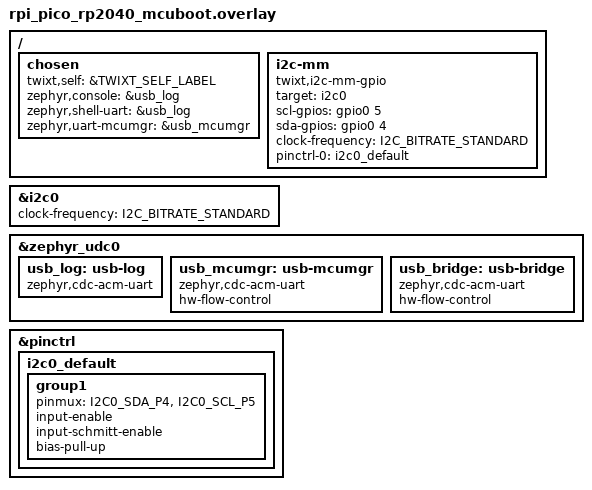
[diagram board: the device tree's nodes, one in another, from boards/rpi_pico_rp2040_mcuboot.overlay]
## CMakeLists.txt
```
# Copyright (c) 2026 Christoph Jans <jans.christoph@gmail.com>
# SPDX-License-Identifier: Apache-2.0

cmake_minimum_required(VERSION 3.20.0)

if(SYSBUILD_CACHE)
  foreach(var MCU ROUTE VERSION)
    file(STRINGS ${SYSBUILD_CACHE} sysbuild_var REGEX "^${var}:")
    if(sysbuild_var)
      string(REGEX REPLACE "^${var}:[A-Z]*=" "" sysbuild_var "${sysbuild_var}")
      set(${var} ${sysbuild_var} CACHE STRING "" FORCE)
    endif()
  endforeach()
endif()
set(MCU pico CACHE STRING "MCU to build: pico, the gateway, or nrf, the one updated")
list(APPEND DTS_EXTRA_CPPFLAGS -DTWIXT_SELF_LABEL=mcu_${MCU})

# ROUTE=service: the twixt MCUmgr service, with twixt,smp-gateway-serial on pico. ROUTE=ble: as
# service, with nrf as the gateway, a twixt,smp-gateway-bt per MCU.
set(ROUTE service CACHE STRING "How SMP gets to the MCUs: service or ble")
if(ROUTE STREQUAL "ble")
  list(APPEND EXTRA_DTC_OVERLAY_FILE ${CMAKE_CURRENT_SOURCE_DIR}/routes/ble_${MCU}.overlay)
  list(APPEND EXTRA_CONF_FILE ${CMAKE_CURRENT_SOURCE_DIR}/routes/ble_${MCU}.conf)
elseif(MCU STREQUAL "pico")
  list(APPEND EXTRA_DTC_OVERLAY_FILE ${CMAKE_CURRENT_SOURCE_DIR}/routes/service_pico.overlay)
endif()

# VERSION: the two builds of nrf that the test updates between
if(VERSION)
  list(APPEND EXTRA_CONF_FILE ${CMAKE_CURRENT_SOURCE_DIR}/routes/version_${VERSION}.conf)
endif()

find_package(Zephyr REQUIRED HINTS $ENV{ZEPHYR_BASE})
project(twixt_smp_update)

target_sources(app PRIVATE src/main.c)
target_sources_ifdef(CONFIG_USB_DEVICE_STACK_NEXT app PRIVATE src/usb.c)
```

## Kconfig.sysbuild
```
# Copyright (c) 2026 Christoph Jans <jans.christoph@gmail.com>
# SPDX-License-Identifier: Apache-2.0

source "share/sysbuild/Kconfig"

config NET_CORE_IMAGE_HCI_IPC
	bool "HCI IPC image on the nRF5340's network core, for ROUTE=ble"
```

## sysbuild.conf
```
# Copyright (c) 2026 Christoph Jans <jans.christoph@gmail.com>
# SPDX-License-Identifier: Apache-2.0

SB_CONFIG_BOOTLOADER_MCUBOOT=y
```

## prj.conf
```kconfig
# Copyright (c) 2026 Christoph Jans <jans.christoph@gmail.com>
# SPDX-License-Identifier: Apache-2.0

CONFIG_I2C=y
CONFIG_LOG=y
CONFIG_LOG_BACKEND_SHOW_COLOR=n
CONFIG_MCUMGR=y
CONFIG_NET_BUF=y
CONFIG_ZCBOR=y
CONFIG_MCUMGR_GRP_OS=y
CONFIG_MCUMGR_GRP_OS_MCUMGR_PARAMS=y
CONFIG_TWIXT_SMP=y
CONFIG_SYSTEM_WORKQUEUE_STACK_SIZE=2048
```

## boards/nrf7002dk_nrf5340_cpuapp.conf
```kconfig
# Copyright (c) 2026 Christoph Jans <jans.christoph@gmail.com>
# SPDX-License-Identifier: Apache-2.0

# The TWIS driver hands over whole messages
CONFIG_I2C_TARGET_BUFFER_MODE=y
CONFIG_I2C_NRFX_TWIS_BUF_SIZE=64
CONFIG_TWIXT_LINK_NACK_RETRY_MS=20

# The image comes over the bus: MCUmgr's img group under MCUboot
CONFIG_BOOTLOADER_MCUBOOT=y
CONFIG_FLASH=y
CONFIG_FLASH_MAP=y
CONFIG_STREAM_FLASH=y
CONFIG_IMG_MANAGER=y
CONFIG_MCUMGR_GRP_IMG=y
CONFIG_REBOOT=y
```

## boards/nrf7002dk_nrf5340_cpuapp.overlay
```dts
/* SPDX-License-Identifier: Apache-2.0 */
/* The bus on the Arduino SDA P1.02, SCL P1.03, at 1.8 V: TWIS2 is the target, the controller
 * software on the same pins (twixt,i2c-mm-gpio), as the TWIM cannot detect lost arbitration.
 */

#include <zephyr/dt-bindings/i2c/i2c.h>

/ {
	chosen {
		twixt,self = &TWIXT_SELF_LABEL;
	};

	i2c-mm {
		compatible = "twixt,i2c-mm-gpio";
		target = <&i2c2>;
		scl-gpios = <&gpio1 3 0>;
		sda-gpios = <&gpio1 2 0>;
		clock-frequency = <I2C_BITRATE_STANDARD>;
		#address-cells = <1>;
		#size-cells = <0>;

#include "../twixt_mcus.dtsi"
	};
};

&arduino_i2c {
	status = "disabled";
};

&i2c2 {
	compatible = "nordic,nrf-twis";
	status = "okay";
	pinctrl-0 = <&i2c2_twis_default>;
	pinctrl-1 = <&i2c2_twis_sleep>;
	pinctrl-names = "default", "sleep";
};

&pinctrl {
	i2c2_twis_default: i2c2_twis_default {
		group1 {
			psels = <NRF_PSEL(TWIS_SDA, 1, 2)>,
				<NRF_PSEL(TWIS_SCL, 1, 3)>;
		};
	};

	i2c2_twis_sleep: i2c2_twis_sleep {
		group1 {
			psels = <NRF_PSEL(TWIS_SDA, 1, 2)>,
				<NRF_PSEL(TWIS_SCL, 1, 3)>;
			low-power-enable;
		};
	};
};
```

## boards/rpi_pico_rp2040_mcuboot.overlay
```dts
/* SPDX-License-Identifier: Apache-2.0 */
/* The bus on GP4 (pin 6), GP5 (pin 7), at 3.3 V: I2C0 is the target, the controller software on
 * the same pins (twixt,i2c-mm-gpio). pinctrl-0 gives the pins back to I2C0.
 */

#include <zephyr/dt-bindings/i2c/i2c.h>

/ {
	chosen {
		twixt,self = &TWIXT_SELF_LABEL;
		zephyr,console = &usb_log;
		zephyr,shell-uart = &usb_log;
		zephyr,uart-mcumgr = &usb_mcumgr;
	};

	i2c-mm {
		compatible = "twixt,i2c-mm-gpio";
		target = <&i2c0>;
		scl-gpios = <&gpio0 5 0>;
		sda-gpios = <&gpio0 4 0>;
		clock-frequency = <I2C_BITRATE_STANDARD>;
		pinctrl-0 = <&i2c0_default>;
		pinctrl-names = "default";
		#address-cells = <1>;
		#size-cells = <0>;

#include "../twixt_mcus.dtsi"
	};
};

&i2c0 {
	clock-frequency = <I2C_BITRATE_STANDARD>;
};

&zephyr_udc0 {
	usb_log: usb-log {
		compatible = "zephyr,cdc-acm-uart";
	};

	usb_mcumgr: usb-mcumgr {
		compatible = "zephyr,cdc-acm-uart";
		/* poll_out: wait instead of dropping */
		hw-flow-control;
	};
};

&pinctrl {
	i2c0_default: i2c0_default {
		group1 {
			pinmux = <I2C0_SDA_P4>, <I2C0_SCL_P5>;
			input-enable;
			input-schmitt-enable;
			bias-pull-up; /* weak; the bus needs its own pull-ups */
		};
	};
};

/* if04: serial SMP from the host */
&zephyr_udc0 {
	usb_bridge: usb-bridge {
		compatible = "zephyr,cdc-acm-uart";
		/* poll_out: wait instead of dropping */
		hw-flow-control;
	};
};
```

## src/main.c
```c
/*
 * Copyright (c) 2026 Christoph Jans <jans.christoph@gmail.com>
 *
 * SPDX-License-Identifier: Apache-2.0
 *
 * The update is all in twixt and Zephyr, see README.rst.
 */

#include <zephyr/kernel.h>
#include <zephyr/logging/log.h>

#include <twixt/twixt.h>

LOG_MODULE_REGISTER(smp_update, LOG_LEVEL_INF);

int main(void)
{
	LOG_INF("%s at 0x%02x", twixt_self_name(), twixt_self_addr());
	return 0;
}
```
